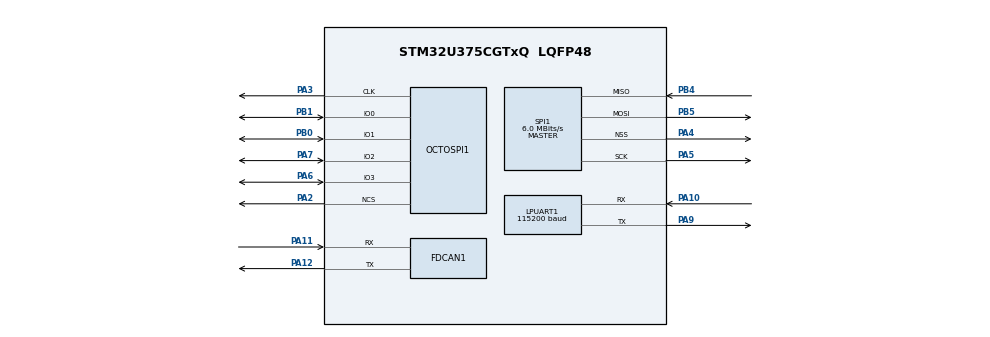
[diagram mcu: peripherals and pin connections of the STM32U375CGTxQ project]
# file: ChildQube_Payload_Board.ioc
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CORTEX_M33_NS.userName=CORTEX_M33
FDCAN1.CalculateBaudRateNominal=250000
FDCAN1.CalculateTimeBitNominal=4000
FDCAN1.CalculateTimeQuantumNominal=1333.3333333333333
LPUART1.BaudRate=115200
LPUART1.SwapParam=UART_ADVFEATURE_SWAP_ENABLE
Mcu.Family=STM32U3
Mcu.Name=STM32U375CGTxQ
Mcu.Package=LQFP48
NVIC.PriorityGroup=NVIC_PRIORITYGROUP_4
PA10.Mode=Asynchronous
PA10.Signal=LPUART1_RX
PA11.Mode=FDCAN_Activate
PA11.Signal=FDCAN1_RX
PA12.Mode=FDCAN_Activate
PA12.Signal=FDCAN1_TX
PA2.Mode=quad_mode
PA2.Signal=OCTOSPI1_NCS
PA3.Mode=quad_mode
PA3.Signal=OCTOSPI1_CLK
PA4.Mode=NSS_Signal_Hard_Output
PA4.Signal=SPI1_NSS
PA5.Mode=Full_Duplex_Master
PA5.Signal=SPI1_SCK
PA6.Mode=OCTOSPI1_IO[3\:0]
PA6.Signal=OCTOSPI1_IO3
PA7.Mode=OCTOSPI1_IO[3\:0]
PA7.Signal=OCTOSPI1_IO2
PA9.Mode=Asynchronous
PA9.Signal=LPUART1_TX
PB0.Mode=OCTOSPI1_IO[3\:0]
PB0.Signal=OCTOSPI1_IO1
PB1.Mode=OCTOSPI1_IO[3\:0]
PB1.Signal=OCTOSPI1_IO0
PB4\ (NJTRST).Mode=Full_Duplex_Master
PB4\ (NJTRST).Signal=SPI1_MISO
PB5.Mode=Full_Duplex_Master
PB5.Signal=SPI1_MOSI
ProjectManager.HeapSize=0x200
ProjectManager.StackSize=0x400
ProjectManager.TargetToolchain=STM32CubeIDE
RCC.ADCFreq_Value=12000000
RCC.AHBFreq_Value=12000000
RCC.APB1Freq_Value=12000000
RCC.APB1TimFreq_Value=12000000
RCC.APB2Freq_Value=12000000
RCC.APB2TimFreq_Value=12000000
RCC.APB3Freq_Value=12000000
RCC.CortexFreq_Value=1500000
RCC.HCLKFreq_Value=12000000
RCC.HSE_VALUE=16000000
RCC.HSI48_VALUE=48000000
RCC.HSI_VALUE=16000000
RCC.LSE_VALUE=32768
RCC.LSIDIV_VALUE=32000
RCC.SYSCLKFreq_VALUE=12000000
RCC.USBFreq_Value=12000000
SPI1.CalculateBaudRate=6.0 MBits/s
SPI1.Direction=SPI_DIRECTION_2LINES
SPI1.Mode=SPI_MODE_MASTER
SPI1.VirtualNSS=VM_NSSHARD
SPI1.VirtualType=VM_MASTER
VP_MEMORYMAP_VS_MEMORYMAP.Mode=CurAppReg
VP_PWR_VS_DBSignals.Mode=DisableDeadBatterySignals
VP_PWR_VS_LPOM.Mode=PowerOptimisation
VP_PWR_VS_SECSignals.Mode=Security/Privilege
board=custom

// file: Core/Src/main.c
/* USER CODE BEGIN Header */
/**
  ******************************************************************************
  * @file           : main.c
  * @brief          : Main program body
  ******************************************************************************
  * @attention
  *
  * Copyright (c) 2026 STMicroelectronics.
  * All rights reserved.
  *
  * This software is licensed under terms that can be found in the LICENSE file
  * in the root directory of this software component.
  * If no LICENSE file comes with this software, it is provided AS-IS.
  *
  ******************************************************************************
  */
/* USER CODE END Header */
#include "main.h"

/* USER CODE BEGIN Includes */
#include <stdio.h>
/* USER CODE END Includes */

FDCAN_HandleTypeDef hfdcan1;

UART_HandleTypeDef hlpuart1;

XSPI_HandleTypeDef hxspi1;

SPI_HandleTypeDef hspi1;

/* USER CODE BEGIN PV */
volatile HAL_StatusTypeDef sd_init_status = HAL_ERROR;
/* USER CODE END PV */

void SystemClock_Config(void);
static void MX_GPIO_Init(void);
static void MX_FDCAN1_Init(void);
static void MX_OCTOSPI1_Init(void);
static void MX_SPI1_Init(void);
static void MX_LPUART1_UART_Init(void);

int main(void)
{

  /* MCU Configuration--------------------------------------------------------*/

  /* Reset of all peripherals, Initializes the Flash interface and the Systick. */
  HAL_Init();

  /* Configure the system clock */
  SystemClock_Config();

  /* Initialize all configured peripherals */
  MX_GPIO_Init();
  MX_FDCAN1_Init();
  MX_OCTOSPI1_Init();
  MX_SPI1_Init();
  MX_LPUART1_UART_Init();
  /* USER CODE BEGIN 2 */
  setvbuf(stdout, NULL, _IONBF, 0);
  sd_init_status = SD_Init();
  /* USER CODE END 2 */

  /* Infinite loop */
  /* USER CODE BEGIN WHILE */
  while (1)
  {
	  printf("Hello World! \r\n");

	  HAL_Delay(500);
    /* USER CODE END WHILE */

  }
}

void SystemClock_Config(void)
{
  RCC_OscInitTypeDef RCC_OscInitStruct = {0};
  RCC_ClkInitTypeDef RCC_ClkInitStruct = {0};

  /** Configure the main internal regulator output voltage
  */
  if (HAL_PWREx_ControlVoltageScaling(PWR_REGULATOR_VOLTAGE_SCALE2) != HAL_OK)
  {
    Error_Handler();
  }

  /** Initializes the CPU, AHB and APB buses clocks
  */
  RCC_OscInitStruct.OscillatorType = RCC_OSCILLATORTYPE_MSIS;
  RCC_OscInitStruct.MSISState = RCC_MSI_ON;
  RCC_OscInitStruct.MSISSource = RCC_MSI_RC0;
  RCC_OscInitStruct.MSISDiv = RCC_MSI_DIV8;
  if (HAL_RCC_OscConfig(&RCC_OscInitStruct) != HAL_OK)
  {
    Error_Handler();
  }

  /** Initializes the CPU, AHB and APB buses clocks
  */
  RCC_ClkInitStruct.ClockType = RCC_CLOCKTYPE_HCLK|RCC_CLOCKTYPE_SYSCLK
                              |RCC_CLOCKTYPE_PCLK1|RCC_CLOCKTYPE_PCLK2
                              |RCC_CLOCKTYPE_PCLK3;
  RCC_ClkInitStruct.SYSCLKSource = RCC_SYSCLKSOURCE_MSIS;
  RCC_ClkInitStruct.AHBCLKDivider = RCC_SYSCLK_DIV1;
  RCC_ClkInitStruct.APB1CLKDivider = RCC_HCLK_DIV1;
  RCC_ClkInitStruct.APB2CLKDivider = RCC_HCLK_DIV1;
  RCC_ClkInitStruct.APB3CLKDivider = RCC_HCLK_DIV1;

  if (HAL_RCC_ClockConfig(&RCC_ClkInitStruct, FLASH_LATENCY_0) != HAL_OK)
  {
    Error_Handler();
  }
}

static void MX_FDCAN1_Init(void)
{

  hfdcan1.Instance = FDCAN1;
  hfdcan1.Init.ClockDivider = FDCAN_CLOCK_DIV1;
  hfdcan1.Init.FrameFormat = FDCAN_FRAME_CLASSIC;
  hfdcan1.Init.Mode = FDCAN_MODE_NORMAL;
  hfdcan1.Init.AutoRetransmission = DISABLE;
  hfdcan1.Init.TransmitPause = DISABLE;
  hfdcan1.Init.ProtocolException = DISABLE;
  hfdcan1.Init.NominalPrescaler = 16;
  hfdcan1.Init.NominalSyncJumpWidth = 1;
  hfdcan1.Init.NominalTimeSeg1 = 1;
  hfdcan1.Init.NominalTimeSeg2 = 1;
  hfdcan1.Init.DataPrescaler = 1;
  hfdcan1.Init.DataSyncJumpWidth = 1;
  hfdcan1.Init.DataTimeSeg1 = 1;
  hfdcan1.Init.DataTimeSeg2 = 1;
  hfdcan1.Init.StdFiltersNbr = 0;
  hfdcan1.Init.ExtFiltersNbr = 0;
  hfdcan1.Init.TxFifoQueueMode = FDCAN_TX_FIFO_OPERATION;
  if (HAL_FDCAN_Init(&hfdcan1) != HAL_OK)
  {
    Error_Handler();
  }

}

static void MX_LPUART1_UART_Init(void)
{

  hlpuart1.Instance = LPUART1;
  hlpuart1.Init.BaudRate = 115200;
  hlpuart1.Init.WordLength = UART_WORDLENGTH_8B;
  hlpuart1.Init.StopBits = UART_STOPBITS_1;
  hlpuart1.Init.Parity = UART_PARITY_NONE;
  hlpuart1.Init.Mode = UART_MODE_TX_RX;
  hlpuart1.Init.HwFlowCtl = UART_HWCONTROL_NONE;
  hlpuart1.Init.OneBitSampling = UART_ONE_BIT_SAMPLE_DISABLE;
  hlpuart1.Init.ClockPrescaler = UART_PRESCALER_DIV1;
  hlpuart1.AdvancedInit.AdvFeatureInit = UART_ADVFEATURE_SWAP_INIT;
  hlpuart1.AdvancedInit.Swap = UART_ADVFEATURE_SWAP_ENABLE;
  hlpuart1.FifoMode = UART_FIFOMODE_DISABLE;
  if (HAL_UART_Init(&hlpuart1) != HAL_OK)
  {
    Error_Handler();
  }
  if (HAL_UARTEx_SetTxFifoThreshold(&hlpuart1, UART_TXFIFO_THRESHOLD_1_8) != HAL_OK)
  {
    Error_Handler();
  }
  if (HAL_UARTEx_SetRxFifoThreshold(&hlpuart1, UART_RXFIFO_THRESHOLD_1_8) != HAL_OK)
  {
    Error_Handler();
  }
  if (HAL_UARTEx_DisableFifoMode(&hlpuart1) != HAL_OK)
  {
    Error_Handler();
  }

}

static void MX_OCTOSPI1_Init(void)
{

  /* OCTOSPI1 parameter configuration*/
  hxspi1.Instance = OCTOSPI1;
  hxspi1.Init.FifoThresholdByte = 1;
  hxspi1.Init.MemoryMode = HAL_XSPI_SINGLE_MEM;
  hxspi1.Init.MemoryType = HAL_XSPI_MEMTYPE_MICRON;
  hxspi1.Init.MemorySize = HAL_XSPI_SIZE_16B;
  hxspi1.Init.ChipSelectHighTimeCycle = 1;
  hxspi1.Init.FreeRunningClock = HAL_XSPI_FREERUNCLK_DISABLE;
  hxspi1.Init.ClockMode = HAL_XSPI_CLOCK_MODE_0;
  hxspi1.Init.WrapSize = HAL_XSPI_WRAP_NOT_SUPPORTED;
  hxspi1.Init.ClockPrescaler = 0;
  hxspi1.Init.SampleShifting = HAL_XSPI_SAMPLE_SHIFT_NONE;
  hxspi1.Init.DelayHoldQuarterCycle = HAL_XSPI_DHQC_DISABLE;
  hxspi1.Init.ChipSelectBoundary = HAL_XSPI_BONDARYOF_NONE;
  hxspi1.Init.DelayBlockBypass = HAL_XSPI_DELAY_BLOCK_BYPASS;
  hxspi1.Init.MaxTran = 0;
  hxspi1.Init.Refresh = 0;
  if (HAL_XSPI_Init(&hxspi1) != HAL_OK)
  {
    Error_Handler();
  }

}

static void MX_SPI1_Init(void)
{

  SPI_AutonomousModeConfTypeDef HAL_SPI_AutonomousMode_Cfg_Struct = {0};

  /* SPI1 parameter configuration*/
  hspi1.Instance = SPI1;
  hspi1.Init.Mode = SPI_MODE_MASTER;
  hspi1.Init.Direction = SPI_DIRECTION_2LINES;
  hspi1.Init.DataSize = SPI_DATASIZE_8BIT;
  hspi1.Init.CLKPolarity = SPI_POLARITY_LOW;
  hspi1.Init.CLKPhase = SPI_PHASE_1EDGE;
  hspi1.Init.NSS = SPI_NSS_SOFT;
  hspi1.Init.BaudRatePrescaler = SPI_BAUDRATEPRESCALER_32;
  hspi1.Init.FirstBit = SPI_FIRSTBIT_MSB;
  hspi1.Init.TIMode = SPI_TIMODE_DISABLE;
  hspi1.Init.CRCCalculation = SPI_CRCCALCULATION_DISABLE;
  hspi1.Init.CRCPolynomial = 0x7;
  hspi1.Init.NSSPMode = SPI_NSS_PULSE_DISABLE;
  hspi1.Init.NSSPolarity = SPI_NSS_POLARITY_LOW;
  hspi1.Init.FifoThreshold = SPI_FIFO_THRESHOLD_01DATA;
  hspi1.Init.MasterSSIdleness = SPI_MASTER_SS_IDLENESS_00CYCLE;
  hspi1.Init.MasterInterDataIdleness = SPI_MASTER_INTERDATA_IDLENESS_00CYCLE;
  hspi1.Init.MasterReceiverAutoSusp = SPI_MASTER_RX_AUTOSUSP_DISABLE;
  hspi1.Init.MasterKeepIOState = SPI_MASTER_KEEP_IO_STATE_DISABLE;
  hspi1.Init.IOSwap = SPI_IO_SWAP_DISABLE;
  hspi1.Init.ReadyMasterManagement = SPI_RDY_MASTER_MANAGEMENT_INTERNALLY;
  hspi1.Init.ReadyPolarity = SPI_RDY_POLARITY_HIGH;
  if (HAL_SPI_Init(&hspi1) != HAL_OK)
  {
    Error_Handler();
  }
  HAL_SPI_AutonomousMode_Cfg_Struct.TriggerState = SPI_AUTO_MODE_DISABLE;
  HAL_SPI_AutonomousMode_Cfg_Struct.TriggerSelection = SPI_GRP1_GPDMA_CH0_TCF_TRG;
  HAL_SPI_AutonomousMode_Cfg_Struct.TriggerPolarity = SPI_TRIG_POLARITY_RISING;
  if (HAL_SPIEx_SetConfigAutonomousMode(&hspi1, &HAL_SPI_AutonomousMode_Cfg_Struct) != HAL_OK)
  {
    Error_Handler();
  }

}

static void MX_GPIO_Init(void)
{
  GPIO_InitTypeDef GPIO_InitStruct = {0};

  /* GPIO Ports Clock Enable */
  __HAL_RCC_GPIOA_CLK_ENABLE();
  __HAL_RCC_GPIOB_CLK_ENABLE();

  /*Configure GPIO pin Output Level */
  HAL_GPIO_WritePin(GPIOA, GPIO_PIN_4, GPIO_PIN_SET);

  /*Configure GPIO pin : PA4 */
  GPIO_InitStruct.Pin = GPIO_PIN_4;
  GPIO_InitStruct.Mode = GPIO_MODE_OUTPUT_PP;
  GPIO_InitStruct.Pull = GPIO_NOPULL;
  GPIO_InitStruct.Speed = GPIO_SPEED_FREQ_LOW;
  HAL_GPIO_Init(GPIOA, &GPIO_InitStruct);

}

/* USER CODE BEGIN 4 */
#ifdef __GNUC__
#define PUTCHAR_PROTOTYPE int __io_putchar(int ch)
#else
#define PUTCHAR_PROTOTYPE int fputc(int ch, FILE *f)
#endif

PUTCHAR_PROTOTYPE
{
  // Replace &huart2 with your specific UART handle (e.g., &huart1, &huart3)
  HAL_UART_Transmit(&hlpuart1, (uint8_t *)&ch, 1, HAL_MAX_DELAY);
  return ch;
}

/* USER CODE END 4 */

void Error_Handler(void)
{
  __disable_irq();
  while (1)
  {
  }
}
